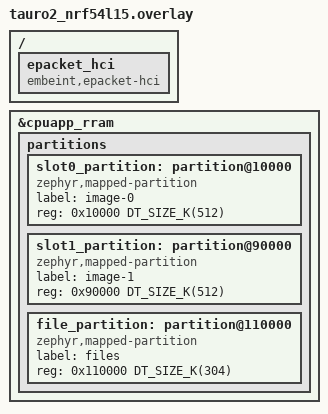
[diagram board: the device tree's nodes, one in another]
/* ePacket HCI support */
/ {
	epacket_hci: epacket_hci {
		compatible = "embeint,epacket-hci";
	};
};

/* Allocate space for patch files */
/delete-node/ &slot0_partition;
/delete-node/ &slot1_partition;

&cpuapp_rram {
	partitions {
		slot0_partition: partition@10000 {
			compatible = "zephyr,mapped-partition";
			label = "image-0";
			reg = <0x10000 DT_SIZE_K(512)>;
		};
		slot1_partition: partition@90000 {
			compatible = "zephyr,mapped-partition";
			label = "image-1";
			reg = <0x90000 DT_SIZE_K(512)>;
		};
		file_partition: partition@110000 {
			compatible = "zephyr,mapped-partition";
			label = "files";
			reg = <0x110000 DT_SIZE_K(304)>;
		};
	};
};
